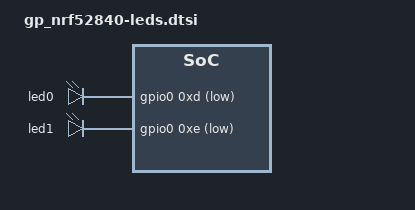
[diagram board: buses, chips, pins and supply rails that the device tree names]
//
// gp-nrf-ble-blinky
// Copyright (c) 2023, Greg PFISTER. MIT Licennse
//
// THE SOFTWARE IS PROVIDED "AS IS", WITHOUT WARRANTY OF ANY KIND, EXPRESS OR
// IMPLIED, INCLUDING BUT NOT LIMITED TO THE WARRANTIES OF MERCHANTABILITY,
// FITNESS FOR A PARTICULAR PURPOSE AND NONINFRINGEMENT.IN NO EVENT SHALL THE
// AUTHORS OR COPYRIGHT HOLDERS BE LIABLE FOR ANY CLAIM, DAMAGES OR OTHER
// LIABILITY, WHETHER IN AN ACTION OF CONTRACT, TORT OR OTHERWISE, ARISING FROM,
// OUT OF OR IN CONNECTION WITH THE SOFTWARE OR THE USE OR OTHER DEALINGS IN THE
// SOFTWARE.
//

/ {

	aliases {
		ledblinky = &led0;
		ledble = &led1;
	};

	leds {
		compatible = "gpio-leds";
        led0: led_0 { // The blinky led
            gpios = < &gpio0 0xd 0x1 >;
        };
        led1: led_1 {
            gpios = < &gpio0 0xe 0x1 >;// The BT status led
        };

    };
};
